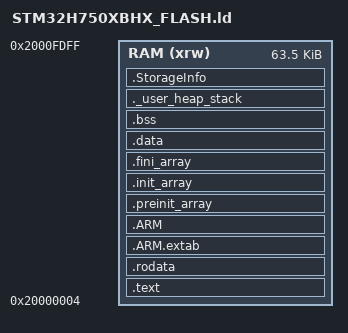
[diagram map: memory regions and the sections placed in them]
/*
*****************************************************************************
**
**  File        : stm32_flash.ld
**
**  Abstract    : Linker script for STM32F103ZG Device with
**                1024KByte FLASH, 96KByte RAM
**
**  Target      : STMicroelectronics STM32
**
**  Environment : Atollic TrueSTUDIO(R)
**
**  Distribution: The file is distributed as is, without any warranty
**                of any kind.
**
**  (c)Copyright Atollic AB.
**  You may use this file as-is or modify it according to the needs of your
**  project. This file may only be built (assembled or compiled and linked)
**  using the Atollic TrueSTUDIO(R) product. The use of this file together
**  with other tools than Atollic TrueSTUDIO(R) is not permitted.
**
*****************************************************************************
*/

/* Entry Point */
ENTRY(Init)

/* Highest address of the user mode stack */
_estack = ORIGIN(RAM) + LENGTH(RAM);	/* end of "RAM" Ram type memory */

_Min_Heap_Size = 0x400;	/* required amount of heap  */
_Min_Stack_Size = 0x400;	/* required amount of stack */

/* Generate 2 segment for loader code and device info */
PHDRS {Loader PT_LOAD ; SgInfo PT_LOAD ; }

/* Specify the memory areas */
MEMORY
{
  RAM (xrw)       : ORIGIN = 0x20000004, LENGTH = 0xFE00-4
}

/* Define output sections */
SECTIONS
{
  /* The program code and other data goes into FLASH */
  .text :
  {
    . = 0x00;
    *(.text)           /* .text sections (code) */
    *(.text*)          /* .text* sections (code) */
    _etext = .;        /* define a global symbols at end of code */
  } >RAM :Loader

  /* Constant data goes into FLASH */
  .rodata :
  {
    *(.rodata)         /* .rodata sections (constants, strings, etc.) */
    *(.rodata*)        /* .rodata* sections (constants, strings, etc.) */
  } >RAM :Loader

  .ARM.extab   : { *(.ARM.extab* .gnu.linkonce.armextab.*) } >RAM
  .ARM : {
    __exidx_start = .;
    *(.ARM.exidx*)
    __exidx_end = .;
  } >RAM :Loader

  .preinit_array     :
  {
    PROVIDE_HIDDEN (__preinit_array_start = .);
    KEEP (*(.preinit_array*))
    PROVIDE_HIDDEN (__preinit_array_end = .);
  } >RAM :Loader
  
  .init_array :
  {
    PROVIDE_HIDDEN (__init_array_start = .);
    KEEP (*(SORT(.init_array.*)))
    KEEP (*(.init_array*))
    PROVIDE_HIDDEN (__init_array_end = .);
  } >RAM :Loader
  
  .fini_array :
  {
    PROVIDE_HIDDEN (__fini_array_start = .);
    KEEP (*(SORT(.fini_array.*)))
    KEEP (*(.fini_array*))
    PROVIDE_HIDDEN (__fini_array_end = .);
  } >RAM :Loader

  /* Initialized data sections goes into RAM, load LMA copy after code */
  .data : 
  {
    _sdata = .;        /* create a global symbol at data start */
    *(.data)           /* .data sections */
    *(.data*)          /* .data* sections */
    _edata = .;        /* define a global symbol at data end */
  } >RAM :Loader

  /* Uninitialized data section */
  .bss :
  {
    /* This is used by the startup in order to initialize the .bss secion */
    _sbss = .;         /* define a global symbol at bss start */
    *(.bss)
    *(.bss*)
    *(COMMON)
    _ebss = .;         /* define a global symbol at bss end */
  } >RAM :Loader

  /* User_heap_stack section, used to check that there is enough "RAM" Ram type memory left */
  ._user_heap_stack :
  {
    . = ALIGN(8);
    PROVIDE ( end = . );
    PROVIDE ( _end = . );
    . = . + _Min_Heap_Size;
    . = . + _Min_Stack_Size;
    . = ALIGN(8);
  } >RAM :Loader

  /* Remove information from the standard libraries */
  /DISCARD/ :
  {
    libc.a ( * )
    libm.a ( * )
    libgcc.a ( * )
  }

  .ARM.attributes 0 : { *(.ARM.attributes) }

  .StorageInfo :
  {
    . = ALIGN(8);
    KEEP ( *Dev_Inf.o (.StorageInfo .StorageInfo*) )
  } >RAM :SgInfo
}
